# DP32G030 register map
File version: 1.0
CPU: CM0 r0p0, little endian, no MPU, no FPU, 4 interrupt priority bits
Registers are 32-bit, read-write, reset 0x0 unless marked. A register's access mark holds for its fields unless they carry their own. Offsets are from the block's base; [hi:lo] are bit positions.

## RTC — RTC unit
Base 0x40069000
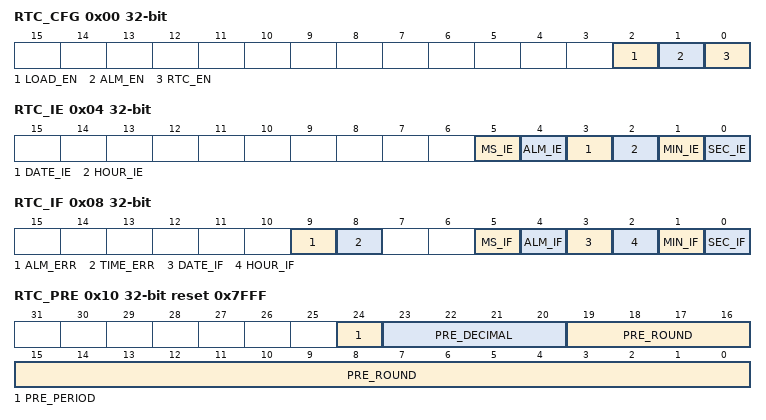
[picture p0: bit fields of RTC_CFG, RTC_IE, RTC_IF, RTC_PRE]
0x00 RTC_CFG — RTC configuration register
  [2] LOAD_EN write-clears — RTC Load Register RTC_TR and RTC_DR Time Setting Value 1: Load the value set in the registers, hardware auto zeroing 0: The value set in the register is not loaded Note: It is recommended to check RTC_IF after RTC_TR and RTC_DR have been configured. TIME_ ERR bit to 0, then turn this bit on again
  [1] ALM_EN — RTC Alarm Clock Function Enable Bit 1: Turn on the alarm clock function, only when ALM_WEEKDAY is 0, this bit is automatically cleared by the hardware 0: Turn off the alarm clock function Note: It is recommended to check that the ALM_ERR bit of RTC_IF is 0 after RTC_AR is configured, and then turn this bit on again.
  [0] RTC_EN — RTC enable bit 1: Open the RTC 0: Turn off RTC
0x04 RTC_IE — RTC interrupt enable register
  [5] MS_IE — 1/2 second interrupt enable bit 1: Enabling 0: not enabled
  [4] ALM_IE — Alarm clock interrupt enable bit 1: Enabling 0: not enabled
  [3] DATE_IE — Day Interrupt Enable Bit 1: Enabling 0: not enabled
  [2] HOUR_IE — Hourly Interrupt Enable Bit 1: Enabling 0: not enabled
  [1] MIN_IE — Minute Interrupt Enable Bit 1: Enabling 0: not enabled
  [0] SEC_IE — Seconds Interrupt Enable Bit 1: Enabling 0: not enabled
0x08 RTC_IF access per field — RTC status register
  [9] ALM_ERR ro — Alarm Setting Valid Flag Bits 1: Wrong alarm setting 0: Alarm clock set correctly
  [8] TIME_ERR ro — Time Setting Valid Flag Bit 1: Time setting error 0: Time set correctly
  [5] MS_IF rw write-1-clears — 1/2 sec interrupt response, active high, write 1 clear
  [4] ALM_IF rw write-1-clears — Alarm Clock Interrupt Response, Active High, Write 1 Clear
  [3] DATE_IF rw write-1-clears — Day Interrupt Response, Active High, Write 1 Clear
  [2] HOUR_IF rw write-1-clears — Hourly Interrupt Response, High Active, Write 1 Clear
  [1] MIN_IF rw write-1-clears — Minute Interrupt Response, Active High, Write 1 Clear
  [0] SEC_IF rw write-1-clears — Interrupt Response in seconds, active high, write 1 clear
0x10 RTC_PRE reset 0x7FFF — RTC prescaler register
  [24] PRE_PERIOD — Fractional calculation cycle selection 0:8 seconds 1:16 seconds
  [23:20] PRE_DECIMAL — prescaled decimal fraction 0: indicates no decimal
  [19:0] PRE_ROUND — prescaled integer part The count value is the configured value plus 1
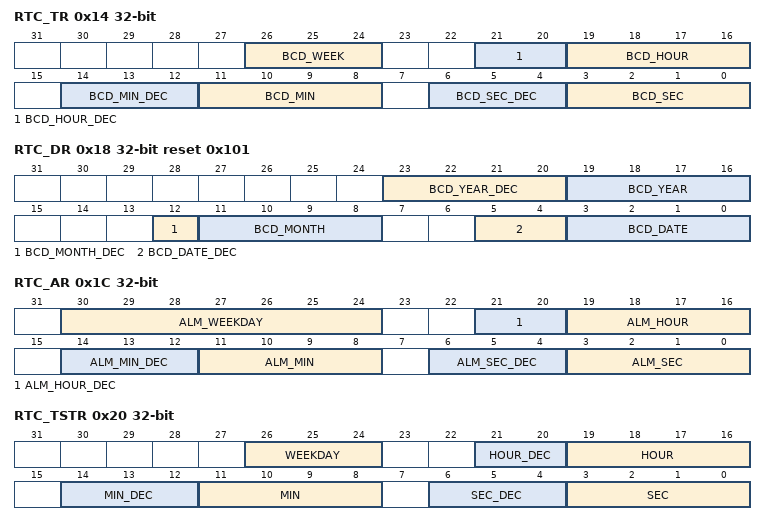
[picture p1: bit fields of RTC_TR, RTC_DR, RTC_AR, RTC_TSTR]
0x14 RTC_TR — RTC time register
  [26:24] BCD_WEEK — Setting the day of the week for the time, 0-6 is legal data. 0: Sunday 1: Monday 2: Tuesday 3: Wednesday 4: Thursday 5: Friday 6: Saturday
  [21:20] BCD_HOUR_DEC — Ten digits (decimal) of the hour to which the set time belongs, 0-2 valid
  [19:16] BCD_HOUR — Set the number of digits (decimal) of the hour to which the time belongs, 0-9 is valid
  [14:12] BCD_MIN_DEC — Ten digits (decimal) of the minute to which the set time belongs, 0-5 valid
  [11:8] BCD_MIN — Set the number of digits (decimal) of the minute to which the time belongs, 0-9 valid
  [6:4] BCD_SEC_DEC — Ten digits (decimal) of the second to which the set time belongs, 0-5 valid
  [3:0] BCD_SEC — Setting the number of digits (decimal) of the second to which the time belongs, 0-9 is valid
0x18 RTC_DR reset 0x101 — RTC date register
  [23:20] BCD_YEAR_DEC — Set the ten digits (decimal) of the month to which the time belongs, 0-1 is valid
  [19:16] BCD_YEAR — Sets the number of digits (decimal) of the month to which the time belongs, 0-9 is valid
  [12] BCD_MONTH_DEC — Set the ten digits (decimal)of the month to which the time belongs, 0-1 is valid
  [11:8] BCD_MONTH — Sets the number of digits (decimal) of the month to which the time belongs, 0-9 is valid
  [5:4] BCD_DATE_DEC — Set the ten digits (decimal) of the date to which the time belongs, 0-3 valid
  [3:0] BCD_DATE — Set the number of digits (decimal) of the date to which the time belongs, 0-9 is valid
0x1C RTC_AR — RTC alarm clock register
  [30:24] ALM_WEEKDAY — The week of the alarm time, each bit indicates one of the days of the week. bit0=1: Sunday bit1=1: Monday bit2=1: Tuesday bit3=1: Wednesday bit4=1: Thursday bit5=1: Friday bit6=1: Saturday Note: With all zeros, the alarm responds only once; with other values, the alarm
  [21:20] ALM_HOUR_DEC — Ten digits of the hour to which the alarm time belongs (decimal), 0-2 Valid
  [19:16] ALM_HOUR — Number of digits (decimal)of the hour to which the alarm time belongs, 0-9 valid
  [14:12] ALM_MIN_DEC — en digits of the minute to which the alarm time belongs (decimal), 0-5 valid
  [11:8] ALM_MIN — Single digit (decimal)of the minute to which the alarm time belongs, valid from 0 to 9
  [6:4] ALM_SEC_DEC — Ten digits of the second to which the alarm time belongs (decimal), 0-5 valid
  [3:0] ALM_SEC — Number of digits (decimal)of the second to which the alarm time belongs, 0-9 valid
0x20 RTC_TSTR ro — RTC current time register
  [26:24] WEEKDAY — The week of the current time, 0-6 are legal data. 0: Sunday 1: Monday 2: Tuesday 3: Wednesday 4: Thursday 5: Friday 6: Saturday
  [21:20] HOUR_DEC — Ten digits of the hour to which the current time belongs (decimal), 0-2 valid
  [19:16] HOUR — The number of digits (decimal) of the hour to which the current time belongs, 0-9 is valid
  [14:12] MIN_DEC — Ten digits (decimal) of the minute to which the current time belongs, 0-5 valid
  [11:8] MIN — The number of digits (decimal)of the minute to which the current time belongs, valid from 0 to 9
  [6:4] SEC_DEC — Ten digits of the second to which the current time belongs (decimal), 0-5 valid
  [3:0] SEC — Number of digits (decimal)of the second to which the current time belongs, 0-9 valid
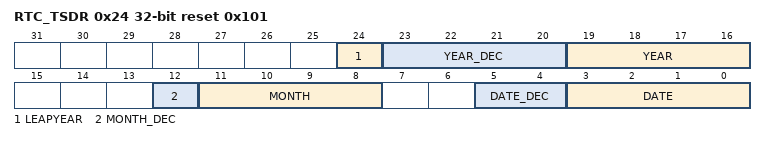
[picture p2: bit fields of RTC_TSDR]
0x24 RTC_TSDR ro reset 0x101 — RTC current date register
  [24] LEAPYEAR
  [23:20] YEAR_DEC — Ten digits (decimal)of the year to which the current time belongs, 0-9 valid
  [19:16] YEAR — Number of digits (decimal)of the chronological year to which the current time belongs, 0-9 valid
  [12] MONTH_DEC — Ten digits of the month to which the current time belongs (decimal), 0-1 valid
  [11:8] MONTH — The number of digits (decimal) of the month to which the current time belongs, 0-9 Valid
  [5:4] DATE_DEC — Ten digits (decimal)of the date to which the current time belongs, 0-3 valid
  [3:0] DATE — Number of digits (decimal)of the date to which the current time belongs, 0-9 valid
0x28 RTC_CNT ro — RTC current count value of the second scale
  [19:0] CNT_20 — 20bit counting bits
0x2C RTC_VALID ro — RTC Current Time Valid Flag Register
  [0] CUR_VALID — Current time valid flag When this bit is judged to be 1, the current time register can be read. (RTC_TSTR, RTC_TSDR, RTC_CNT)
